# STM32N655 register map
File version: 1.0
CPU: CM55 r0p1, little endian, no MPU, FPU, vendor SysTick, 8 interrupt priority bits
Registers are 32-bit, read-write, reset 0x0 unless marked. A register's access mark holds for its fields unless they carry their own. Offsets are from the block's base; [hi:lo] are bit positions; {n}, {i} and the like mark numbered series.

## TIM16 — General purpose timers
Base 0x42004400
Same registers: TIM16_S 0x52004400
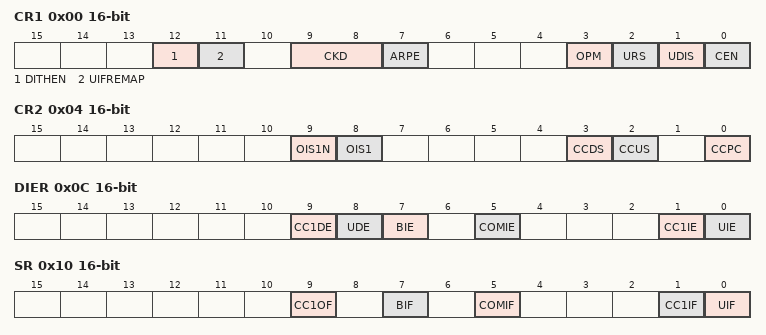
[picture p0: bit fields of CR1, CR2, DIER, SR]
0x00 CR1 16-bit — TIM16 control register 1
  [12] DITHEN — Dithering enable
  [11] UIFREMAP — UIF status bit remapping
  [9:8] CKD — Clock division
  [7] ARPE — Auto-reload preload enable
  [3] OPM — One pulse mode
  [2] URS — Update request source
  [1] UDIS — Update disable
  [0] CEN — Counter enable
0x04 CR2 16-bit — TIM16 control register 2
  [9] OIS1N — Output Idle state 1 (tim_oc1n output)
  [8] OIS1 — Output Idle state 1 (tim_oc1 output)
  [3] CCDS — Capture/compare DMA selection
  [2] CCUS — Capture/compare control update selection
  [0] CCPC — Capture/compare preloaded control
0x0C DIER 16-bit — TIM16 DMA/interrupt enable register
  [9] CC1DE — Capture/Compare 1 DMA request enable
  [8] UDE — Update DMA request enable
  [7] BIE — Break interrupt enable
  [5] COMIE — COM interrupt enable
  [1] CC1IE — Capture/Compare 1 interrupt enable
  [0] UIE — Update interrupt enable
0x10 SR 16-bit — TIM16 status register
  [9] CC1OF — Capture/Compare 1 overcapture flag
  [7] BIF — Break interrupt flag
  [5] COMIF — COM interrupt flag
  [1] CC1IF — Capture/Compare 1 interrupt flag
  [0] UIF — Update interrupt flag
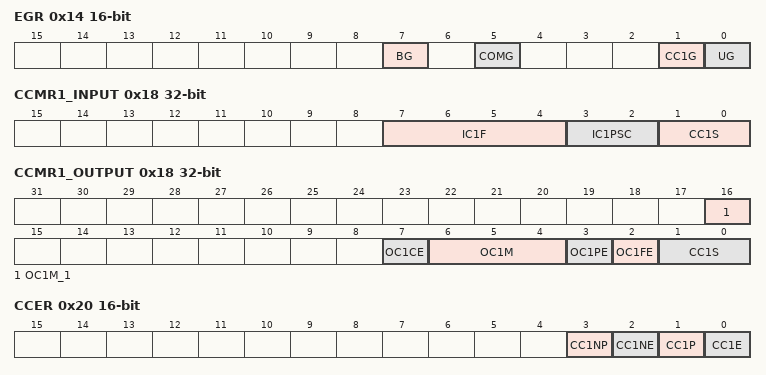
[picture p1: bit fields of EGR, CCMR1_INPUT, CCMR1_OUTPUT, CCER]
0x14 EGR 16-bit wo — TIM16 event generation register
  [7] BG — Break generation
  [5] COMG — Capture/Compare control update generation
  [1] CC1G — Capture/Compare 1 generation
  [0] UG — Update generation
0x18 CCMR1_INPUT — TIM16 capture/compare mode register 1
  [7:4] IC1F — Input capture 1 filter
  [3:2] IC1PSC — Input capture 1 prescaler
  [1:0] CC1S — Capture/Compare 1 selection
0x18 CCMR1_OUTPUT (alternate view of CCMR1_INPUT) — TIM16 capture/compare mode register 1
  [16] OC1M_1 — OC1M[3]
  [7] OC1CE — Output Compare 1 clear enable
  [6:4] OC1M — OC1M[2:0]: Output Compare 1 mode
  [3] OC1PE — Output Compare 1 preload enable
  [2] OC1FE — Output Compare 1 fast enable
  [1:0] CC1S — Capture/Compare 1 selection
0x20 CCER 16-bit — TIM16 capture/compare enable register
  [3] CC1NP — Capture/Compare 1 complementary output polarity
  [2] CC1NE — Capture/Compare 1 complementary output enable
  [1] CC1P — Capture/Compare 1 output polarity
  [0] CC1E — Capture/Compare 1 output enable
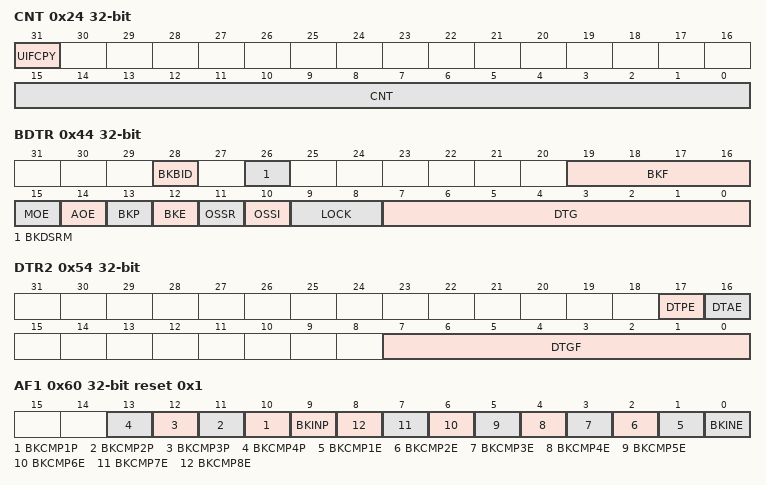
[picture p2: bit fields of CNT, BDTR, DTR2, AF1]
0x24 CNT access per field — TIM16 counter
  [31] UIFCPY ro — UIF Copy
  [15:0] CNT rw — Counter value
0x28 PSC 16-bit — TIM16 prescaler
  [15:0] PSC — Prescaler value
0x2C ARR reset 0xFFFF — TIM16 auto-reload register
  [19:0] ARR — Auto-reload value
0x30 RCR 16-bit — TIM16 repetition counter register
  [7:0] REP — Repetition counter reload value
0x34 CCR1 — TIM16 capture/compare register 1
  [19:0] CCR1 — Capture/Compare 1 value
0x44 BDTR — TIM16 break and dead-time register
  [28] BKBID — Break Bidirectional
  [26] BKDSRM — Break Disarm
  [19:16] BKF — Break filter
  [15] MOE — Main output enable
  [14] AOE — Automatic output enable
  [13] BKP — Break polarity
  [12] BKE — Break enable
  [11] OSSR — Off-state selection for Run mode
  [10] OSSI — Off-state selection for Idle mode
  [9:8] LOCK — Lock configuration
  [7:0] DTG — Dead-time generator setup
0x54 DTR2 — TIM16 timer deadtime register 2
  [17] DTPE — Deadtime preload enable
  [16] DTAE — Deadtime asymmetric enable
  [7:0] DTGF — Dead-time falling edge generator setup
0x5C TISEL — TIM16 input selection register
  [3:0] TI1SEL — selects tim_ti1_in[15:0] input
0x60 AF1 reset 0x1 — TIM16 alternate function register 1
  [n+9] BKCMP{n}P (n=1..4) — tim_brk_cmp{n} input polarity
  [9] BKINP — TIMx_BKIN input polarity
  [n] BKCMP{n}E (n=1..8) — tim_brk_cmp{n} enable
  [0] BKINE — TIMx_BKIN input enable
0x64 AF2 — TIM16 alternate function register 2
  [18:16] OCRSEL — tim_ocref_clr source selection
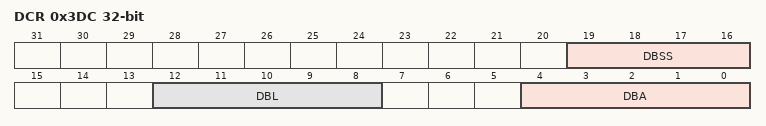
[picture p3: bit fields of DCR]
0x3DC DCR — TIM16 DMA control register
  [19:16] DBSS — DMA burst source selection
  [12:8] DBL — DMA burst length
  [4:0] DBA — DMA base address
0x3E0 DMAR — TIM16/TIM17 DMA address for full transfer
  [31:0] DMAB — DMA register for burst accesses

## TIM17 — General purpose timers
Base 0x42004800
Same registers: TIM17_S 0x52004800
Registers as TIM16 (with TIM16 read as TIM17); these are added or differ:
0x3E0 DMAR — TIM16/TIM17 DMA address for full transfer
  [31:0] DMAB — DMA register for burst accesses
